# SAM9X75D2GN4 device description
Architecture: ARM926EJ-S; Family: SAM9; Series: SAM9X7
Registers are 32-bit, read-write, reset 0x0 unless marked. A register's access mark holds for its fields unless they carry their own. Offsets are from the block's base; [hi:lo] are bit positions; {n}, {i} and the like mark numbered series; 'fields as' and 'values as' point back to an identical list.

## UHPFS — USB Host Full-Speed Port
Instances: UHPHS_OHCI 0x00600000
0x00 UHPFS_HcRevision ro reset 0x10 — OHCI Revision Number Register
  [7:0] REV — OHCI Revision Number
    16=This read-only field contains the BCD representation of the version of the HCI specification that is implemented by this HC. For example, a value of 11h corresponds to version 1.1. All of the HC implementations that are compliant with this specification will have a value of 10h.
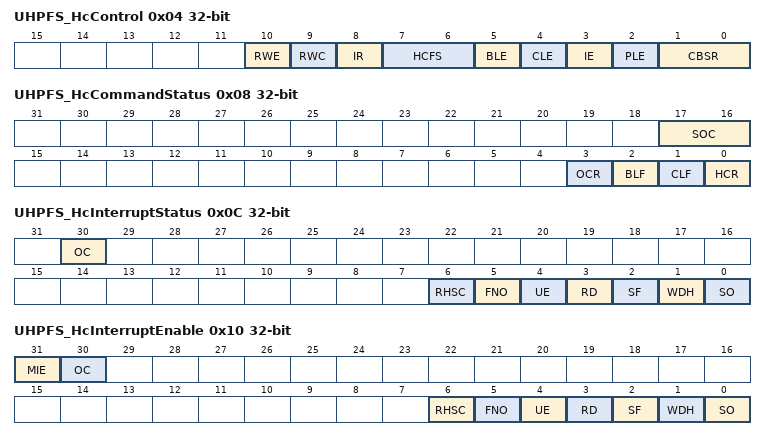
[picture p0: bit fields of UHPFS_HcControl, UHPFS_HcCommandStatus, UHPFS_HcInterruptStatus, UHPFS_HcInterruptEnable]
0x04 UHPFS_HcControl — HC Operating Mode Register
  [10] RWE — Remote Wakeup Enable
  [9] RWC — Remote Wakeup Connected
  [8] IR — Interrupt Routing
    0=The USB1.1 host controller does not provide an SMI interrupt. This bit must be 0 to allow the USB1.1 host controller interrupt to propagate to the MPU level 2 interrupt controller.
  [7:6] HCFS — Host Controller Functional State
    0=USB reset; 1=USB resume; 2=USB operational; 3=USB suspend
  [5] BLE — Bulk List Enable
    0=The bulk ED list is not processed in the next 1 ms frame. The host controller driver can modify the bulk ED list. If the driver removes the ED pointed to by the UHPFS_HcBulkCurrentED register from the ED list, it must update the UHPFS_HcBulkCurrentED register to point to a current ED before it reenables the bulk list.; 1=Enables processing of the bulk ED list. The UHPFS_HcBulkHeadED register must be 0 or point to a valid ED before setting this bit. The UHPFS_HcBulkCurrentED register must be 0 or point to a valid ED before setting this bit.
  [4] CLE — ControL List Enable
    0=The control ED list is not processed in the next 1 ms frame. The host controller driver can modify the control ED list. If the driver removes the ED pointed to by the UHPFS_HcControlCurrentED register from the ED list, it must update the UHPFS_HcControlCurrentED register to point to a current ED before it reenables the control list.; 1=Enables processing of the control ED list. The UHPFS_HcControlHeadED register must be 0 or point to a valid ED before setting this bit. The UHPFS_HcControlCurrentED register must be 0 or point to a valid ED before setting this bit.
  [3] IE — Isochronous Enable
    0=Isochronous EDs are not processed. The USB1.1 host controller checks this bit every time it finds an isochronous ED in the periodic list.; 1=Enables processing of isochronous EDs in the next frame, if not in the current frame
  [2] PLE — Periodic List Enable
    0=Periodic ED lists are not processed. Periodic list processing is disabled beginning with the next frame.; 1=Enables processing of the periodic ED lists. Periodic list processing begins in the next frame.
  [1:0] CBSR — Control/Bulk Service Ratio
    0=1 control ED per bulk ED; 1=2 control EDs per bulk ED; 2=3 control EDs per bulk ED; 3=4 control EDs per bulk ED
0x08 UHPFS_HcCommandStatus — HC Command and Status Register
  [17:16] SOC — Scheduling Overrun Count (read-only)
  [3] OCR — Ownership Change Request (read/write)
  [2] BLF — Bulk List Filled (read/write)
  [1] CLF — Control List Filled (read/write)
  [0] HCR — Host Controller Reset (read/write)
    0=No effect; 1=Initiates a software reset of the USB1.1 host controller. This transitions the USB1.1 host controller to the USB suspend state. This resets most USB1.1 host controller OHCI registers. OHCI register accesses must not be attempted until a read of this bit returns a 0. A write of 1 to this bit does not reset the root hub and does not signal USB reset to downstream USB functions.
0x0C UHPFS_HcInterruptStatus — HC Interrupt and Status Register
  [30] OC — Ownership Change (read-only)
  [6] RHSC — Root Hub Status Change (read/write, write '1' to clear)
    0=A root hub status change has not occurred; 1=A root hub status change has occurred
  [5] FNO — Frame Number Overflow (read/write, write '1' to clear)
    0=A frame number overflow has not occurred; 1=A frame number overflow has occurred
  [4] UE — Unrecoverable Error (read/write, write '1' to clear)
    0=An unrecoverable error has not occurred; 1=An unrecoverable error has occurred on the OCPI bus, or that an isochronous TD PSW field condition code was not set to Not Accessed when the USB1.1 host controller attempted to perform a transfer using that PSW/offset pair
  [3] RD — Resume Detected (read/write, write '1' to clear)
    0=A downstream device has not issued a resume request; 1=A downstream device has issued a resume request
  [2] SF — Start of Frame (read/write, write '1' to clear)
    0=A SOF has not been issued; 1=A SOF has been issued
  [1] WDH — Write Done Head (read/write, write '1' to clear)
    0=USB1.1 host controller has not updated the UHPFS_HcDoneHead register; 1=USB1.1 host controller has updated the UHPFS_HcDoneHead register
  [0] SO — Scheduling Overrun (read/write, write '1' to clear)
    0=A scheduling overrun has not occurred; 1=A scheduling overrun has occurred
0x10 UHPFS_HcInterruptEnable — HC Interrupt Enable Register
  [31] MIE — Master Interrupt Enable (read/write, write '1' to set)
    0=OHCI interrupt sources are ignored and USB1.1 host controller interrupts are not propagated to the level 2 interrupt controller; 1=Allows other enabled OHCI interrupt sources to propagate to the level 2 interrupt controller
  [30] OC — Ownership Change (read-only)
    0=Ignore; 1=Enable interrupt generation due to Ownership Change
  [6] RHSC — Root Hub Status Change (read/write, write '1' to set)
    0=Root hub status change interrupts do not propagate; 1=When MIE is 1, allows root hub status change interrupts to propagate to the level 2 interrupt controller
  [5] FNO — Frame Number Overflow (read/write, write '1' to set)
    0=Frame number overflow interrupts do not propagate; 1=When MIE is 1, allows frame number overflow interrupts to propagate to the level 2 interrupt controller
  [4] UE — Unrecoverable Error (read/write, write '1' to set)
    0=Unrecoverable error interrupts do not propagate; 1=When MIE is 1, allows unrecoverable error interrupts to propagate to the level 2 interrupt controller
  [3] RD — Resume Detected (read/write, write '1' to set)
    0=Resume detected interrupts do not propagate; 1=When MIE is 1, allows resume detected interrupts to propagate to the level 2 interrupt controller
  [2] SF — Start of Frame (read/write, write '1' to set)
    0=Start of frame interrupts do not propagate; 1=When MIE is 1, allows start of frame interrupts to propagate to the level 2 interrupt controller
  [1] WDH — Write Done Head (read/write, write '1' to set)
    0=Write done head interrupts do not propagate; 1=When MIE is 1, allows write done head interrupts to propagate to the level 2 interrupt controller
  [0] SO — Scheduling Overrun (read/write, write '1' to set)
    0=Scheduling overrun interrupts do not propagate; 1=When MIE is 1, allows scheduling overrun interrupts to propagate to the level 2 interrupt controller
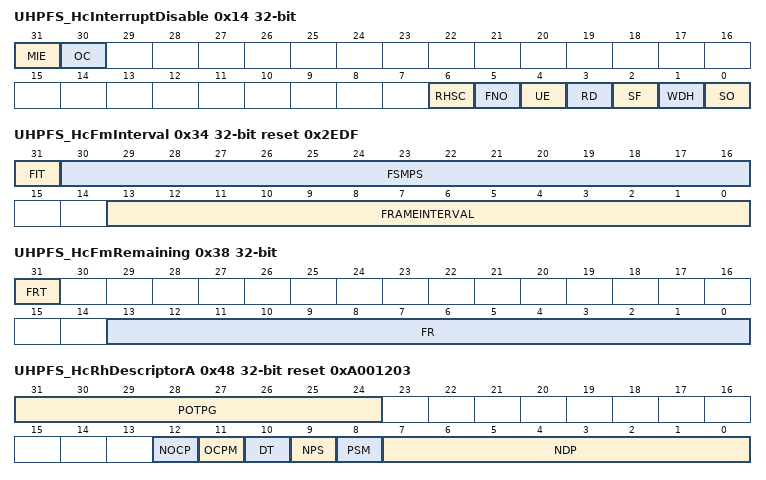
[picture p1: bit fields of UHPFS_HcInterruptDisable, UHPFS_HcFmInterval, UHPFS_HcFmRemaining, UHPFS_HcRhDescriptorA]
0x14 UHPFS_HcInterruptDisable — HC Interrupt Disable Register
  [31] MIE — Master Interrupt Enable (read/write)
    0=No effect; 1=Clears the MIE bit in the UHPFS_HcInterruptEnable register
  [30] OC — Ownership Change (read-only)
    0=Ignore; 1=Disable interrupt generation due to Ownership Change
  [6] RHSC — Root Hub Status Change (read/write)
    0=No effect; 1=Clears the RHSC bit in the UHPFS_HcInterruptEnable register
  [5] FNO — Frame Number Overflow (read/write)
    0=No effect; 1=Clears the FNO bit in the UHPFS_HcInterruptEnable register
  [4] UE — Unrecoverable Error (read/write)
    0=No effect; 1=Clears the UE bit in the UHPFS_HcInterruptEnable register
  [3] RD — Resume Detected (read/write)
    0=No effect; 1=Clears the RD bit in the UHPFS_HcInterruptEnable register
  [2] SF — Start of Frame (read/write)
    0=No effect; 1=Clears the SF bit in the UHPFS_HcInterruptEnable register
  [1] WDH — Write Done Head (read/write)
    0=No effect; 1=Clears the WDH bit in the UHPFS_HcInterruptEnable register
  [0] SO — Scheduling Overrun (read/write)
    0=No effect; 1=Clears the SO bit in the UHPFS_HcInterruptEnable register
0x18 UHPFS_HcHCCA — HC HCCA Address Register
  [31:8] HCCA — Physical Address of the Beginning of the HCCA
0x1C UHPFS_HcPeriodCurrentED — HC Current Periodic Register
  [31:4] PCED — Physical Address of the Current ED on the Periodic ED list
0x20 UHPFS_HcControlHeadED — HC Head Control Register
  [31:4] CHED — Physical Address of the Head ED on the Control ED list
0x24 UHPFS_HcControlCurrentED — HC Current Control Register
  [31:4] CCED — Physical Address of the Current ED on the Control ED List
0x28 UHPFS_HcBulkHeadED — HC Head Bulk Register
  [31:4] BHED — Physical Address of the Head ED on the Bulk ED List
0x2C UHPFS_HcBulkCurrentED — HC Current Bulk Register
  [31:4] BCED — Physical Address of the Current ED on the Bulk ED List
0x30 UHPFS_HcDoneHead — HC Head Done Register
  [31:4] DH — Physical Address of the Last TD that has added to the done queue
0x34 UHPFS_HcFmInterval reset 0x2EDF — HC Frame Interval Register
  [31] FIT — Frame Interval Toggle
  [30:16] FSMPS — Largest Data Packet
  [13:0] FRAMEINTERVAL
0x38 UHPFS_HcFmRemaining — HC Frame Remaining Register
  [31] FRT — Frame Remaining Toggle
  [13:0] FR — Frame Remaining
0x3C UHPFS_HcFmNumber — HC Frame Number Register
  [15:0] FN — Frame Number
0x40 UHPFS_HcPeriodicStart — HC Periodic Start Register
  [13:0] PS — Periodic Start
0x44 UHPFS_HcLSThreshold reset 0x628 — HC Low-Speed Threshold Register
  [13:0] LST — Low-Speed Threshold
0x48 UHPFS_HcRhDescriptorA reset 0xA001203 — HC Root Hub A Register
  [31:24] POTPG — Power-On to Power-good Time (read/write)
  [12] NOCP — No Overcurrent Protection (read/write)
    1=Because the device does not provide signals to allow connection of external overcurrent indication signals to the USB1.1 host controller, this bit defaults to 1 that indicates that the USB1.1 host controller does not implement overcurrent protection inputs. This bit has no relationship to the OTG controller register bits that relate to VBUS.
  [11] OCPM — Overcurrent Protection Mode (read/write)
    0=Because the device does not provide host controller overcurrent protection input signals, this bit has no effect. This bit has no relationship to the OTG controller register bits that relate to VBUS.
  [10] DT — Device Type (read-only)
    0=This bit is always 0, which indicates that the USB1.1 host controller implemented is not a compound device
  [9] NPS — No Power Switching (read/write)
    1=Because the device does not provide connections from the USB1.1 host controller to control external VBUS switching, this bit defaults to 1 that indicates that VBUS power switching is not supported and that power is available to all downstream ports when the USB1.1 host controller is powered. This bit has no relationship to the OTG controller register bits that relate to VBUS. System software can update this register to simplify host controller driver and/or OTG driver coding.
  [8] PSM — Power Switching Mode (read/write)
    0=Because the device does not provide signals from the USB1.1 host controller to control external VBUS switching, this bit defaults to 0 that indicates that all ports are powered at the same time
  [7:0] NDP — Number of Downstream Ports (read-only)
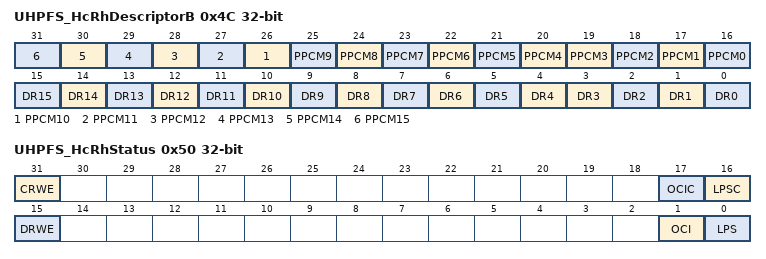
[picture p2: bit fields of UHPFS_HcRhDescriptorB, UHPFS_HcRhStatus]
0x4C UHPFS_HcRhDescriptorB — HC Root Hub B Register
  [n+16] PPCM{n} (n=4..15) — Port Power Control Mask
  [19] PPCM3 — Port Power Control Mask for Downstream Port 3
    0=Global power control is implemented for downstream port 3; 1=Per-port power control is implemented for downstream port 3
  [18] PPCM2 — Port Power Control Mask for Downstream Port 2
    0=Global power control is implemented for downstream port 2; 1=Per-port power control is implemented for downstream port 2
  [17] PPCM1 — Port Power Control Mask for Downstream Port 1
    0=Global power control is implemented for downstream port 1; 1=Per-port power control is implemented for downstream port 1
  [16] PPCM0 — Port Power Control Mask
  [n] DR{n} (n=4..15) — Device Removable
  [3] DR3 — Device Removable Bit for Downstream Port 3
    0=Downstream port 3 may have a removable device attached; 1=Downstream port 3 has a nonremovable device attached
  [2] DR2 — Device Removable Bit for Downstream Port 2
    0=Downstream port 2 may have a removable device attached; 1=Downstream port 2 has a nonremovable device attached
  [1] DR1 — Device Removable Bit for Downstream Port 1
    0=Downstream port 1 may have a removable device attached; 1=Downstream port 1 has a nonremovable device attached
  [0] DR0 — Device Removable
0x50 UHPFS_HcRhStatus — HC Root Hub Status Register
  [31] CRWE — Clear Remote Wakeup Enable (read/write)
    0=No effect; 1=Clears the device remote wakeup enable bit
  [17] OCIC — Overcurrent Indication Change (read/write)
    0=No effect; 1=Clears this bit
  [16] LPSC — Local Power Status Change (read/write)
    0=Because the root hub does not support the local power status feature, this bit defaults to 0 and has no effect. This bit has no relationship to the OTG controller register bits that relate to VBUS. System software can update this register to simplify host controller driver and/or OTG driver coding.
  [15] DRWE — Device Remote Wakeup Enable (read/write)
    0=A write of 0 has no effect. Connect status change events do not cause a transition from USB suspend to USB resume state and the resume detected interrupt is not changed.; 1=A write of 1 sets the device remote wakeup enable bit. This bit enables a connect status change event to be treated as a resume event, which causes a transition from USB suspend to USB resume state and sets the resume detected interrupt status bit.
  [1] OCI — Overcurrent Indicator (read-only)
    0=Because the device does not provide signals for external hardware to report overcurrent status to the USB1.1 host controller, this bit is always 0. This bit has no relationship to the OTG controller register bits that relate to VBUS.
  [0] LPS — Local Power Status (read/write)
    values as LPSC
{0x54+4i} UHPFS_HcRhPortStatus[{i}] (i=0..2) reset 0x100 — HC Port Status and Control Register (ndp = 0)
  [20] PRSC — Port Reset Status Change (read/write, write '1' to clear)
    0=Port x port reset status bit has not changed; 1=Port x port reset status bit has changed
  [19] OCIC — Overcurrent Indicator Change (read/write)
    0=Because the device does not provide inputs for signaling external overcurrent indication to the USB1.1 host controller, this bit is always 0. Overcurrent monitoring, if required, must be handled through some other mechanism. This bit has no relationship to the OTG controller register bits that relate to VBUS.
  [18] PSSC — Port Suspend Status Change (read/write, write '1' to clear)
    0=Port x port suspend status has not changed; 1=Port x port suspend status has changed. Suspend status is considered to have changed only after the resume pulse, low-speed EOP, and 3-ms synchronization delays have been completed.
  [17] PESC — Port Enable Status Change (read/write, write '1' to clear)
    0=Port x port enable status has not changed; 1=Port x port enable status has changed
  [16] CSC — Connect Status Change (read/write, write '1' to clear)
    0=Port x current connect status has not changed; 1=Port x current connect status has changed due to a connect or disconnect event. If current connect status is 0 when a set port reset, set port enable, or set port suspend write occurs, then this bit is set.
  [9] CPP — Low-speed Device Attached/clear Port Power (read/write)
    0=Full-speed device is attached to port x; 1=Low-speed device is attached to port x
  [9] LSDA — Low-speed Device Attached/clear Port Power (read/write)
    values as CPP
  [8] PPS — Port Power Status/set Port Power (read/write)
    0=Port x power is disabled; 1=Port x power is enabled
  [8] SPP — Port Power Status/set Port Power (read/write)
    0=Port x power is disabled; 1=Port x power is enabled
  [4] PRS — Port Reset Status/set Port Reset (read/write)
    0=USB reset is not being sent to port x; 1=Port x is signaling the USB reset
  [4] SPR — Port Reset Status/set Port Reset (read/write)
    values as PRS
  [3] CSS — Port Overcurrent Indicator/clear Suspend Status (read/write)
    0=Port x port overcurrent condition has not occurred; 1=Port x port overcurrent condition has occurred
  [3] POCI — Port Overcurrent Indicator/clear Suspend Status (read/write)
    values as CSS
  [2] PSS — Port Suspend Status/set Port Suspend (read/write)
    0=Port x is not in the USB suspend state; 1=Port x is in the USB suspend state or is in the resume sequence
  [2] SPS — Port Suspend Status/set Port Suspend (read/write)
    values as PSS
  [1] PES — Port Enable Status/set Port Enable (read/write)
    0=Port x is disabled; 1=Port x is enabled
  [1] SPE — Port Enable Status/set Port Enable (read/write)
    0=Port x is disabled; 1=Port x is enabled
  [0] CCS — Port Current Connection Status/clear Port Enable (read/write)
    0=No USB device is attached to port x; 1=USB device is attached to port x
  [0] CPE — Port Current Connection Status/clear Port Enable (read/write)
    values as CCS
